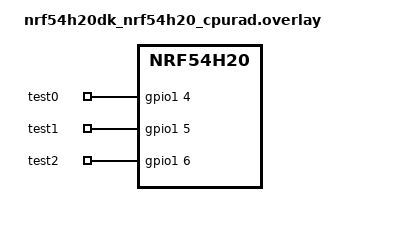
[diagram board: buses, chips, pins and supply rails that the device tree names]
/*
 * Copyright (c) 2024 Nordic Semiconductor ASA
 * SPDX-License-Identifier: LicenseRef-Nordic-5-Clause
 */

/ {
	test_gpio {
		compatible = "gpio-keys";
		test0: test0 {
			gpios = <&gpio1 4 GPIO_ACTIVE_HIGH>;
		};
		test1: test1 {
			gpios = <&gpio1 5 GPIO_ACTIVE_HIGH>;
		};
		test2: test2 {
			gpios = <&gpio1 6 GPIO_ACTIVE_HIGH>;
		};
	};
};

&uart135 {
	/delete-property/ hw-flow-control;
};

&ipc0 {
	compatible = "zephyr,ipc-icmsg";
	/delete-property/ tx-blocks;
	/delete-property/ rx-blocks;
};
